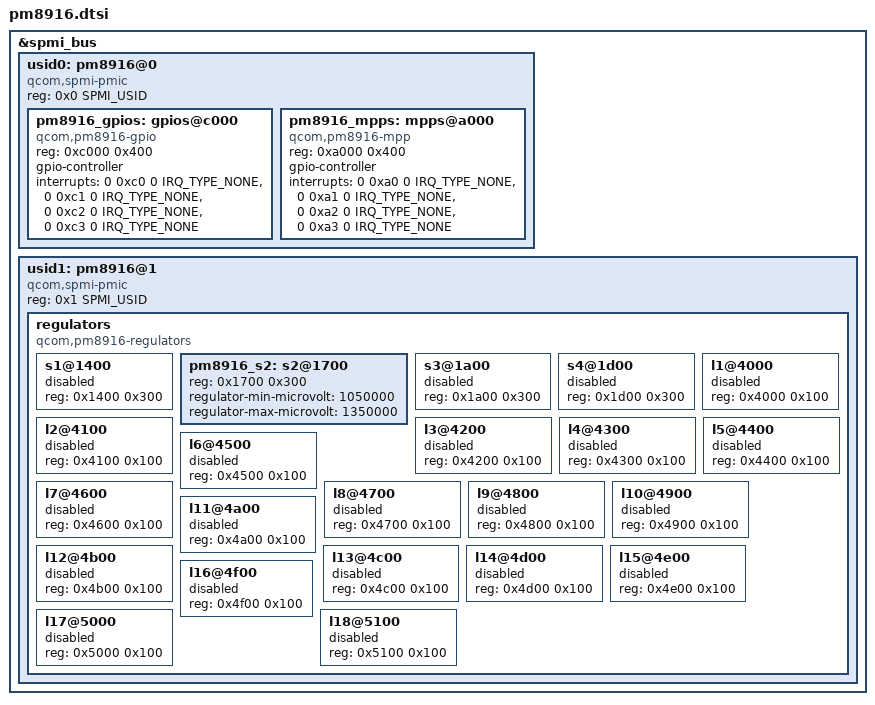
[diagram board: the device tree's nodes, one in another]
#include <dt-bindings/interrupt-controller/irq.h>
#include <dt-bindings/spmi/spmi.h>

&spmi_bus {

	usid0: pm8916@0 {
		compatible ="qcom,spmi-pmic";
		reg = <0x0 SPMI_USID>;
		#address-cells = <1>;
		#size-cells = <0>;

		pm8916_gpios: gpios@c000 {
			compatible = "qcom,pm8916-gpio";
			reg = <0xc000 0x400>;
			gpio-controller;
			#gpio-cells = <2>;
			interrupts = <0 0xc0 0 IRQ_TYPE_NONE>,
				     <0 0xc1 0 IRQ_TYPE_NONE>,
				     <0 0xc2 0 IRQ_TYPE_NONE>,
				     <0 0xc3 0 IRQ_TYPE_NONE>;
		};

		pm8916_mpps: mpps@a000 {
			compatible = "qcom,pm8916-mpp";
			reg = <0xa000 0x400>;
			gpio-controller;
			#gpio-cells = <2>;
			interrupts = <0 0xa0 0 IRQ_TYPE_NONE>,
				     <0 0xa1 0 IRQ_TYPE_NONE>,
				     <0 0xa2 0 IRQ_TYPE_NONE>,
				     <0 0xa3 0 IRQ_TYPE_NONE>;
		};
	};

	usid1: pm8916@1 {
		compatible ="qcom,spmi-pmic";
		reg = <0x1 SPMI_USID>;
		#address-cells = <1>;
		#size-cells = <0>;

		regulators {
			compatible = "qcom,pm8916-regulators";
			#address-cells = <1>;
			#size-cells = <1>;

			s1@1400 {
				reg = <0x1400 0x300>;
				status = "disabled";
			};

			pm8916_s2: s2@1700 {
				reg = <0x1700 0x300>;
				status = "ok";
				regulator-min-microvolt = <1050000>;
				regulator-max-microvolt = <1350000>;
			};

			s3@1a00 {
				reg = <0x1a00 0x300>;
				status = "disabled";
			};

			s4@1d00 {
				reg = <0x1d00 0x300>;
				status = "disabled";
			};

			l1@4000 {
				reg = <0x4000 0x100>;
				status = "disabled";
			};

			l2@4100 {
				reg = <0x4100 0x100>;
				status = "disabled";
			};

			l3@4200 {
				reg = <0x4200 0x100>;
				status = "disabled";
			};

			l4@4300 {
				reg = <0x4300 0x100>;
				status = "disabled";
			};

			l5@4400 {
				reg = <0x4400 0x100>;
				status = "disabled";
			};

			l6@4500 {
				reg = <0x4500 0x100>;
				status = "disabled";
			};

			l7@4600 {
				reg = <0x4600 0x100>;
				status = "disabled";
			};

			l8@4700 {
				reg = <0x4700 0x100>;
				status = "disabled";
			};

			l9@4800 {
				reg = <0x4800 0x100>;
				status = "disabled";
			};

			l10@4900 {
				reg = <0x4900 0x100>;
				status = "disabled";
			};

			l11@4a00 {
				reg = <0x4a00 0x100>;
				status = "disabled";
			};

			l12@4b00 {
				reg = <0x4b00 0x100>;
				status = "disabled";
			};

			l13@4c00 {
				reg = <0x4c00 0x100>;
				status = "disabled";
			};

			l14@4d00 {
				reg = <0x4d00 0x100>;
				status = "disabled";
			};

			l15@4e00 {
				reg = <0x4e00 0x100>;
				status = "disabled";
			};

			l16@4f00 {
				reg = <0x4f00 0x100>;
				status = "disabled";
			};

			l17@5000 {
				reg = <0x5000 0x100>;
				status = "disabled";
			};

			l18@5100 {
				reg = <0x5100 0x100>;
				status = "disabled";
			};
		};

	};
};
